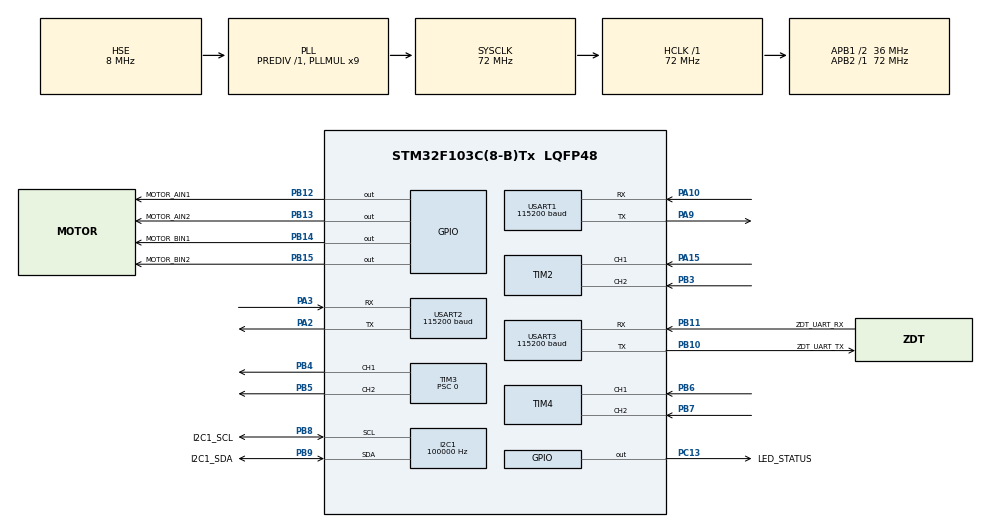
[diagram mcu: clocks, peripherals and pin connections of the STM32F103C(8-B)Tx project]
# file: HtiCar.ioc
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Mcu.Family=STM32F1
Mcu.Name=STM32F103C(8-B)Tx
Mcu.Package=LQFP48
I2C1.ClockSpeed=100000
I2C1.DutyCycle=I2C_DUTYCYCLE_2
NVIC.I2C1_ER_IRQn=true\:5\:0\:true\:false\:true\:true\:true\:true
NVIC.I2C1_EV_IRQn=true\:5\:0\:true\:false\:true\:true\:true\:true
NVIC.PriorityGroup=NVIC_PRIORITYGROUP_4
NVIC.USART1_IRQn=true\:5\:0\:true\:false\:true\:true\:true\:true
NVIC.USART2_IRQn=true\:5\:0\:true\:false\:true\:true\:true\:true
NVIC.USART3_IRQn=true\:5\:0\:true\:false\:true\:true\:true\:true
PA10.GPIO_PuPd=GPIO_PULLUP
PA10.Mode=Asynchronous
PA10.Signal=USART1_RX
PA13.Mode=Serial_Wire
PA13.Signal=SYS_JTMS-SWDIO
PA14.Mode=Serial_Wire
PA14.Signal=SYS_JTCK-SWCLK
PA15.Signal=S_TIM2_CH1_ETR
PA2.Mode=Asynchronous
PA2.Signal=USART2_TX
PA3.GPIO_PuPd=GPIO_PULLUP
PA3.Mode=Asynchronous
PA3.Signal=USART2_RX
PA9.Mode=Asynchronous
PA9.Signal=USART1_TX
PB10.GPIO_Label=ZDT_UART_TX
PB10.Mode=Asynchronous
PB10.Signal=USART3_TX
PB11.GPIO_Label=ZDT_UART_RX
PB11.GPIO_PuPd=GPIO_PULLUP
PB11.Mode=Asynchronous
PB11.Signal=USART3_RX
PB12.GPIO_Label=MOTOR_AIN1
PB12.GPIO_ModeDefaultOutputPP=GPIO_MODE_OUTPUT_PP
PB12.GPIO_PuPd=GPIO_NOPULL
PB12.GPIO_Speed=GPIO_SPEED_FREQ_LOW
PB12.PinState=GPIO_PIN_RESET
PB12.Signal=GPIO_Output
PB13.GPIO_Label=MOTOR_AIN2
PB13.GPIO_ModeDefaultOutputPP=GPIO_MODE_OUTPUT_PP
PB13.GPIO_PuPd=GPIO_NOPULL
PB13.GPIO_Speed=GPIO_SPEED_FREQ_LOW
PB13.PinState=GPIO_PIN_RESET
PB13.Signal=GPIO_Output
PB14.GPIO_Label=MOTOR_BIN1
PB14.GPIO_ModeDefaultOutputPP=GPIO_MODE_OUTPUT_PP
PB14.GPIO_PuPd=GPIO_NOPULL
PB14.GPIO_Speed=GPIO_SPEED_FREQ_LOW
PB14.PinState=GPIO_PIN_RESET
PB14.Signal=GPIO_Output
PB15.GPIO_Label=MOTOR_BIN2
PB15.GPIO_ModeDefaultOutputPP=GPIO_MODE_OUTPUT_PP
PB15.GPIO_PuPd=GPIO_NOPULL
PB15.GPIO_Speed=GPIO_SPEED_FREQ_LOW
PB15.PinState=GPIO_PIN_RESET
PB15.Signal=GPIO_Output
PB3.Signal=S_TIM2_CH2
PB4.Signal=S_TIM3_CH1
PB5.Signal=S_TIM3_CH2
PB6.Signal=S_TIM4_CH1
PB7.Signal=S_TIM4_CH2
PB8.GPIO_Label=I2C1_SCL
PB8.GPIO_PuPd=GPIO_PULLUP
PB8.Mode=I2C
PB8.Signal=I2C1_SCL
PB9.GPIO_Label=I2C1_SDA
PB9.GPIO_PuPd=GPIO_PULLUP
PB9.Mode=I2C
PB9.Signal=I2C1_SDA
PC13-TAMPER-RTC.GPIO_Label=LED_STATUS
PC13-TAMPER-RTC.GPIO_ModeDefaultOutputPP=GPIO_MODE_OUTPUT_PP
PC13-TAMPER-RTC.GPIO_PuPd=GPIO_NOPULL
PC13-TAMPER-RTC.GPIO_Speed=GPIO_SPEED_FREQ_LOW
PC13-TAMPER-RTC.PinState=GPIO_PIN_SET
PC13-TAMPER-RTC.Signal=GPIO_Output
PD0-OSC_IN.Mode=HSE-External-Oscillator
PD0-OSC_IN.Signal=RCC_OSC_IN
PD1-OSC_OUT.Mode=HSE-External-Oscillator
PD1-OSC_OUT.Signal=RCC_OSC_OUT
ProjectManager.HeapSize=0x200
ProjectManager.StackSize=0x400
ProjectManager.TargetToolchain=CMake
RCC.AHBFreq_Value=72000000
RCC.APB1CLKDivider=RCC_HCLK_DIV2
RCC.APB1Freq_Value=36000000
RCC.APB1TimFreq_Value=72000000
RCC.APB2Freq_Value=72000000
RCC.APB2TimFreq_Value=72000000
RCC.HCLKFreq_Value=72000000
RCC.HSE_VALUE=8000000
RCC.PLLMUL=RCC_PLL_MUL9
RCC.PLLSourceVirtual=RCC_PLLSOURCE_HSE
RCC.SYSCLKFreq_VALUE=72000000
RCC.SYSCLKSource=RCC_SYSCLKSOURCE_PLLCLK
RCC.USBFreq_Value=72000000
SH.S_TIM2_CH1_ETR.0=TIM2_CH1,Encoder_Interface
SH.S_TIM2_CH2.0=TIM2_CH2,Encoder_Interface
SH.S_TIM3_CH1.0=TIM3_CH1,PWM Generation1 CH1
SH.S_TIM3_CH2.0=TIM3_CH2,PWM Generation2 CH2
SH.S_TIM4_CH1.0=TIM4_CH1,Encoder_Interface
SH.S_TIM4_CH2.0=TIM4_CH2,Encoder_Interface
TIM2.EncoderMode=TIM_ENCODERMODE_TI12
TIM2.IC1Filter=8
TIM2.IC2Filter=8
TIM3.Channel-PWM\ Generation1\ CH1=TIM_CHANNEL_1
TIM3.Channel-PWM\ Generation2\ CH2=TIM_CHANNEL_2
TIM3.Period=3599
TIM3.Prescaler=0
TIM4.EncoderMode=TIM_ENCODERMODE_TI12
TIM4.IC1Filter=8
TIM4.IC2Filter=8
USART1.BaudRate=115200
USART1.VirtualMode=VM_ASYNC
USART2.BaudRate=115200
USART2.VirtualMode=VM_ASYNC
USART3.BaudRate=115200
USART3.VirtualMode=VM_ASYNC
VP_TIM3_VS_ClockSourceINT.Mode=Internal
board=custom

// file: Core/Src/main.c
/* USER CODE BEGIN Header */
/**
  ******************************************************************************
  * @file           : main.c
  * @brief          : Main program body
  ******************************************************************************
  * @attention
  *
  * Copyright (c) 2026 STMicroelectronics.
  * All rights reserved.
  *
  * This software is licensed under terms that can be found in the LICENSE file
  * in the root directory of this software component.
  * If no LICENSE file comes with this software, it is provided AS-IS.
  *
  ******************************************************************************
  */
/* USER CODE END Header */
#include "main.h"
#include "tim.h"
#include "usart.h"
#include "gpio.h"
#include "i2c.h"

/* USER CODE BEGIN Includes */
#include "app_main.h"

/* USER CODE END Includes */

void SystemClock_Config(void);

int main(void)
{

  /* MCU Configuration--------------------------------------------------------*/

  /* Reset of all peripherals, Initializes the Flash interface and the Systick. */
  HAL_Init();

  /* Configure the system clock */
  SystemClock_Config();

  /* Initialize all configured peripherals */
  MX_GPIO_Init();
  MX_I2C1_Init();
  MX_TIM2_Init();
  MX_TIM3_Init();
  MX_TIM4_Init();
  MX_USART1_UART_Init();
  MX_USART2_UART_Init();
  MX_USART3_UART_Init();
  /* USER CODE BEGIN 2 */
  App_Init();

  /* USER CODE END 2 */

  /* Infinite loop */
  while (1)
  {

    /* USER CODE BEGIN 3 */
    App_Run();
  }
  /* USER CODE END 3 */
}

void SystemClock_Config(void)
{
  RCC_OscInitTypeDef RCC_OscInitStruct = {0};
  RCC_ClkInitTypeDef RCC_ClkInitStruct = {0};

  /** Initializes the RCC Oscillators according to the specified parameters
  * in the RCC_OscInitTypeDef structure.
  */
  RCC_OscInitStruct.OscillatorType = RCC_OSCILLATORTYPE_HSE;
  RCC_OscInitStruct.HSEState = RCC_HSE_ON;
  RCC_OscInitStruct.HSEPredivValue = RCC_HSE_PREDIV_DIV1;
  RCC_OscInitStruct.HSIState = RCC_HSI_ON;
  RCC_OscInitStruct.PLL.PLLState = RCC_PLL_ON;
  RCC_OscInitStruct.PLL.PLLSource = RCC_PLLSOURCE_HSE;
  RCC_OscInitStruct.PLL.PLLMUL = RCC_PLL_MUL9;
  if (HAL_RCC_OscConfig(&RCC_OscInitStruct) != HAL_OK)
  {
    Error_Handler();
  }

  /** Initializes the CPU, AHB and APB buses clocks
  */
  RCC_ClkInitStruct.ClockType = RCC_CLOCKTYPE_HCLK|RCC_CLOCKTYPE_SYSCLK
                              |RCC_CLOCKTYPE_PCLK1|RCC_CLOCKTYPE_PCLK2;
  RCC_ClkInitStruct.SYSCLKSource = RCC_SYSCLKSOURCE_PLLCLK;
  RCC_ClkInitStruct.AHBCLKDivider = RCC_SYSCLK_DIV1;
  RCC_ClkInitStruct.APB1CLKDivider = RCC_HCLK_DIV2;
  RCC_ClkInitStruct.APB2CLKDivider = RCC_HCLK_DIV1;

  if (HAL_RCC_ClockConfig(&RCC_ClkInitStruct, FLASH_LATENCY_2) != HAL_OK)
  {
    Error_Handler();
  }
}

void Error_Handler(void)
{
  /* USER CODE BEGIN Error_Handler_Debug */
  /* STBY is hard-wired high: force both PWM channels and direction pins low. */
  TIM3->CCR1 = 0U;
  TIM3->CCR2 = 0U;
  GPIOB->BRR = MOTOR_AIN1_Pin|MOTOR_AIN2_Pin|MOTOR_BIN1_Pin|MOTOR_BIN2_Pin;
  /* User can add his own implementation to report the HAL error return state */
  __disable_irq();
  while (1)
  {
  }
  /* USER CODE END Error_Handler_Debug */
}
